# EOS-S3 register map
File version: 0.1
CPU: CM4 r0p1, selectable endian, MPU, FPU, 3 interrupt priority bits
Registers are 32-bit, read-write, reset 0x0 unless marked. A register's access mark holds for its fields unless they carry their own. Offsets are from the block's base; [hi:lo] are bit positions; {n}, {i} and the like mark numbered series.

## SPI_TLC — Communication Manager - Top Level controller
Base 0x40050000
0x00 DEVICEIDBYTE 8-bit reset 0x21 — Device ID, Read Only. 0x21, the Protocol of accessing this SFR is different, See Device ID read Page for detail
  [7:0] DeviceIDByte ro
{0x9+i} CM_FIFO_{i}_DATA 8-bit (i=0..3) — PF Bank FIFO {i} Read Port
  [7:0] DATA ro — PF FIFO Read Port
0x20 MemAddrByte0 8-bit — Memory Address, It is representing AHB Byte Address bit [7:0]. Bit 7:0 R/W, Default All 0. Bit [1:0] will be ignored since only Support Word Access
0x21 MemAddrByte1 8-bit — AHB Memory Address, It is representing AHB Byte Address bit [15:8]. Bit 7:0 R/W, Default All 0. Once write to this SFR, an AHB memory Read Could be Trigger. See 'TLC AHB Memory Read Trigger' worksheet for detail.
0x22 MemAddrByte2 8-bit — AHB Memory Address, It is representing AHB Byte Address bit [23:16]. Bit 7:0 R/W, Default All 0
0x23 MemAddrByte3 8-bit — AHB Memory Address, It is representing AHB Byte Address bit [31:24]. Bit 7:0 R/W,Default All 0
0x28 MemDataByte0 8-bit — First Byte (LSB) of AHB memory data
0x29 MemDataByte1 8-bit — Second byte of AHB memory data
0x2A MemDataByte2 8-bit — Third byte of AHB memory data
0x2B MemDataByte3 8-bit — Forth byte of AHB memory data, once write to this SFR. 1. Trigger a AHB memory Write. 2. Auto Increment the AHB memory address (MemAddrByte0/MemAddrByte1) by 4 since AHB memory Address is in Byte Granunality. (offset 0x20~0x21, 64KB range)
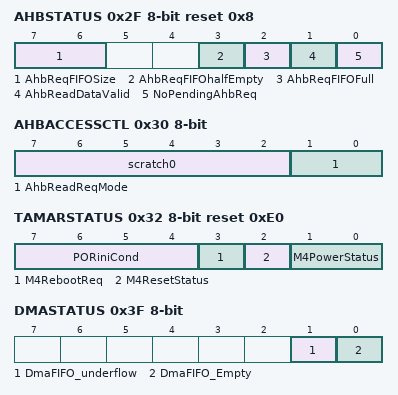
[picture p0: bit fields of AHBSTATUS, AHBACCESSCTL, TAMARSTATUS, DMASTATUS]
0x2F AHBSTATUS 8-bit reset 0x8
  [7:6] AhbReqFIFOSize ro — 0 if FIFO is 4 entries, 1 if FIFO is 8 entries.
  [3] AhbReqFIFOhalfEmpty ro — Set if AHB Address/Data/Command FIFO is less than half full.
  [2] AhbReqFIFOFull ro — Set if AHB Address/Data/Command FIFO is Full. (Read Only)
  [1] AhbReadDataValid ro — Set if AHB Read Data is Ready. This bit is Auto Clear Once a new AHB read Access kick off and Auto Set once AHB read data is valid.
  [0] NoPendingAhbReq ro — If set, there's pending AHB Memory Read/Write request
0x30 AHBACCESSCTL 8-bit — AHB access control register
  [7:2] scratch0 — General Purpose Registers
  [1:0] AhbReadReqMode — AHB Memory Read Option. 2'b11 : If MemAddrByte[1:0] is 2'b11, then AHB Memory Read will not be automatically triggered once MemAddrByte1 is written Other : The AHB Memory Read behavior is same as S2, Once MemAddrByte1 is written, AHB Memory read is triggered.
0x31 SCRATCHBYTE 8-bit — General Purpose Registers, R/W, Default 0
0x32 TAMARSTATUS 8-bit reset 0xE0 — ???
  [7:4] PORiniCond ro — 0xE value if POR trigger, It reflect the value of rfupmu offset 00C
  [3] M4RebootReq ro — This bit is reflect the value on RFUPMU offset 3EC. It will not set for cold start.
    0=no_reload_need (No Code reload is neccesary); 1=reload_needed (Need to Re-Load the Code in AP mode)
  [2] M4ResetStatus ro — Indicates if the M4 Subsystem reset is released (not core reset)
    0=reset_released (M4 Subsystem reset is released.); 1=reset_not_release (M4 Subsystem reset is NOT released.)
  [1:0] M4PowerStatus ro — Indicate the M4 Power Status
    0=Active mode; 1=Deep Sleep mode; 2=Shut down mode; 3=Clock off mode
0x36 DMADEBUGCTL0 8-bit — Set bit to clear the DMA FIFO. Firmware can only set this bit to 1 after set DmaClear bit to 1 and Program this bit to 0 after clear DmaClear bit
  [0] DmaFifoClear
0x37 DMADEBUGCTL1 8-bit — Set bit to Reset the DMA engineer. Firmware needs to clear it before kick off the new DMA Transfer. Need to do a dummy Read on this SFR after program this bit
  [0] DmaClear
0x38 DMAADDR0 8-bit — DMA Starting Address, It is representing AHB Byte Address bit [7:0]. Bit [1:0] will be ignored since only Support Word Access
0x39 DMAADDR1 8-bit — DMA Starting Address, It is representing AHB Byte Address bit [15:8].
0x3A DMAADDR2 8-bit — DMA Starting Address, It is representing AHB Byte Address bit [23:16]
0x3B DMAADDR3 8-bit — DMA Starting Address, It is representing AHB Byte Address bit [31:24]
0x3C DMABURSTSIZE0 8-bit — DMA transfer size indicates the number of bytes to be read out ( X ). The minimum transfer size is 4 bytes. Program the value for number of bytes to read minus 4 bytes ( X -4 ), into the 2 registers. DmaBurstSize0 register represents the BurstSize[7:0]. DmaBurstSize1 register represents the BurstSize[15:8]. Lower 2 bits are ignored by hardware, since it only supports Word Access. This means only multiples of 4 are supported. For example: To read 4 bytes, you would write: DmaBurstSize0 = 0, DmaBurstSize1 = 0. To read 8 bytes, you would write: DmaBurstSize0 = 4, DmaBurstSize1 = 0 … To read 256 bytes, you would write: DmaBurstSize0 = FC, DmaBurstSize1 = 0. To read 260 bytes, you would write: DmaBurstSize0 = 0, DmaBurstSize1 = 1 ... and so on, etc.
  [7:0] DMABurstSize0 — LSB Byte of DMA transfer size. It is representing BurstSize[7:0]
0x3D DMABURSTSIZE1 8-bit — MSB Byte of DMA transfer size. it is representing BurstSize[15:8]. Max transfer size is 64KB, Once it is written, DMA will be kickoff unless DmaBurstSize0[1:0] = 2'b10. Min. Transfer Size will be 4 Bytes once DMA is Kick Off ({DmaBurstSize0, DmaBurstSize1} == 0x0}
  [7:0] DMABurstSize1 — MSB Byte of DMA transfer size. It is representing BurstSize[15:8]
0x3E Reserved_dummy 8-bit — For dummy write purpose.
  [7:0] dummy wo — For dummy write purpose
0x3F DMASTATUS 8-bit
  [1] DmaFIFO_underflow ro — Set if DMA hit underflow condition
  [0] DmaFIFO_Empty ro — Set if DMA FIFO is Empty
0x40 DMARDDATA 8-bit — DMA Read Data Port
  [7:0] DmaRdData ro
